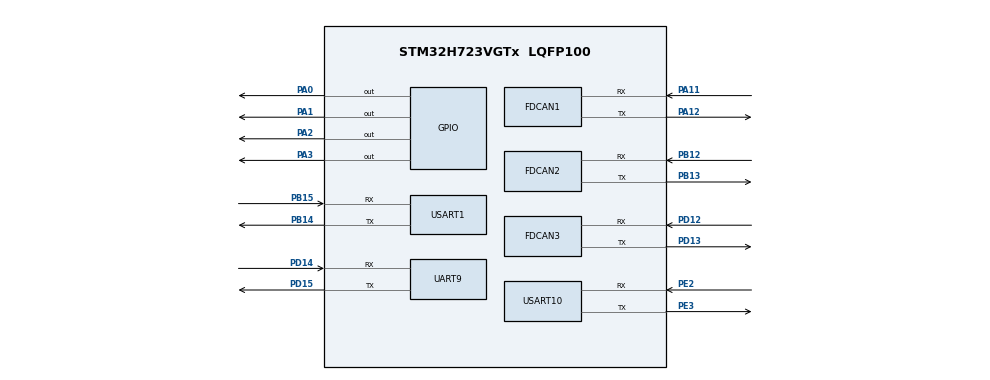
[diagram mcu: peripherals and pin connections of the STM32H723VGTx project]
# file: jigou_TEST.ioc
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CORTEX_M7.default_mode_Activation=1
FDCAN1.CalculateBaudRateNominal=1000000
FDCAN1.CalculateTimeBitNominal=1000
FDCAN1.CalculateTimeQuantumNominal=50.0
FDCAN1.ExtFiltersNbr=1
FDCAN1.NominalPrescaler=5
FDCAN1.NominalTimeSeg1=14
FDCAN1.NominalTimeSeg2=5
FDCAN1.RxBuffersNbr=0
FDCAN1.RxFifo0ElmtsNbr=32
FDCAN1.RxFifo1ElmtsNbr=0
FDCAN1.StdFiltersNbr=1
FDCAN1.TxFifoQueueElmtsNbr=8
FDCAN2.CalculateBaudRateNominal=2083333
FDCAN2.CalculateTimeBitNominal=480
FDCAN2.CalculateTimeQuantumNominal=160.0
FDCAN2.MessageRAMOffset=852
FDCAN3.CalculateBaudRateNominal=2083333
FDCAN3.CalculateTimeBitNominal=480
FDCAN3.CalculateTimeQuantumNominal=160.0
FDCAN3.MessageRAMOffset=1704
Mcu.Family=STM32H7
Mcu.Name=STM32H723VGTx
Mcu.Package=LQFP100
NVIC.FDCAN1_IT0_IRQn=true\:0\:0\:false\:false\:true\:true\:true\:true
NVIC.FDCAN2_IT0_IRQn=true\:0\:0\:false\:false\:true\:true\:true\:true
NVIC.FDCAN3_IT0_IRQn=true\:0\:0\:false\:false\:true\:true\:true\:true
NVIC.PriorityGroup=NVIC_PRIORITYGROUP_4
NVIC.USART10_IRQn=true\:0\:0\:false\:false\:true\:true\:true\:true
NVIC.USART1_IRQn=true\:0\:0\:false\:false\:true\:true\:true\:true
PA0.GPIO_PuPd=GPIO_PULLDOWN
PA0.Signal=GPIO_Output
PA1.GPIO_PuPd=GPIO_PULLDOWN
PA1.Signal=GPIO_Output
PA11.Mode=FDCAN_Activate
PA11.Signal=FDCAN1_RX
PA12.Mode=FDCAN_Activate
PA12.Signal=FDCAN1_TX
PA13(JTMS/SWDIO).Mode=Serial_Wire
PA13(JTMS/SWDIO).Signal=DEBUG_JTMS-SWDIO
PA14(JTCK/SWCLK).Mode=Serial_Wire
PA14(JTCK/SWCLK).Signal=DEBUG_JTCK-SWCLK
PA2.GPIO_PuPd=GPIO_PULLDOWN
PA2.Signal=GPIO_Output
PA3.GPIO_PuPd=GPIO_PULLDOWN
PA3.Signal=GPIO_Output
PB12.Mode=FDCAN_Activate
PB12.Signal=FDCAN2_RX
PB13.Mode=FDCAN_Activate
PB13.Signal=FDCAN2_TX
PB14.Mode=Asynchronous
PB14.Signal=USART1_TX
PB15.Mode=Asynchronous
PB15.Signal=USART1_RX
PD12.Mode=FDCAN_Activate
PD12.Signal=FDCAN3_RX
PD13.Mode=FDCAN_Activate
PD13.Signal=FDCAN3_TX
PD14.Mode=Asynchronous
PD14.Signal=UART9_RX
PD15.Mode=Asynchronous
PD15.Signal=UART9_TX
PE2.Mode=Asynchronous
PE2.Signal=USART10_RX
PE3.Mode=Asynchronous
PE3.Signal=USART10_TX
PH0-OSC_IN.Mode=HSE-External-Oscillator
PH0-OSC_IN.Signal=RCC_OSC_IN
PH1-OSC_OUT.Mode=HSE-External-Oscillator
PH1-OSC_OUT.Signal=RCC_OSC_OUT
ProjectManager.HeapSize=0x200
ProjectManager.StackSize=0x400
ProjectManager.TargetToolchain=MDK-ARM V5.32
RCC.ADCFreq_Value=250000000
RCC.APB1Freq_Value=125000000
RCC.APB2Freq_Value=125000000
RCC.APB3Freq_Value=125000000
RCC.APB4Freq_Value=125000000
RCC.CortexFreq_Value=500000000
RCC.D1PPRE=RCC_APB3_DIV2
RCC.D2PPRE1=RCC_APB1_DIV2
RCC.D2PPRE2=RCC_APB2_DIV2
RCC.D3PPRE=RCC_APB4_DIV2
RCC.DIVM1=5
RCC.DIVM2=5
RCC.DIVM3=8
RCC.DIVN1=100
RCC.DIVN2=100
RCC.DIVP1=1
RCC.DIVQ1=5
RCC.DIVQ2=5
RCC.DIVR1=5
RCC.HCLKFreq_Value=250000000
RCC.HPRE=RCC_HCLK_DIV2
RCC.PLL2FRACN=0
RCC.PLL3FRACN=0
RCC.PLLFRACN=0
RCC.PLLSourceVirtual=RCC_PLLSOURCE_HSE
RCC.SYSCLKFreq_VALUE=500000000
RCC.SYSCLKSource=RCC_SYSCLKSOURCE_PLLCLK
RCC.USBFreq_Value=100000000
USART1.VirtualMode-Asynchronous=VM_ASYNC
USART10.VirtualMode=VM_ASYNC
VP_MEMORYMAP_VS_MEMORYMAP.Mode=CurAppReg
VP_TIM6_VS_ClockSourceINT.Mode=Enable_Timer
board=custom

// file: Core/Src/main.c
/* USER CODE BEGIN Header */
/**
  ******************************************************************************
  * @file           : main.c
  * @brief          : Main program body
  ******************************************************************************
  * @attention
  *
  * Copyright (c) 2026 STMicroelectronics.
  * All rights reserved.
  *
  * This software is licensed under terms that can be found in the LICENSE file
  * in the root directory of this software component.
  * If no LICENSE file comes with this software, it is provided AS-IS.
  *
  ******************************************************************************
  */
/* USER CODE END Header */
#include "main.h"
#include "fdcan.h"
#include "tim.h"
#include "usart.h"
#include "gpio.h"

/* USER CODE BEGIN Includes */
#include "my_main.h"
#include "vofa.h"
/* USER CODE END Includes */

/* USER CODE BEGIN PV */

static uint8_t vofa_rx_byte;

/* USER CODE END PV */

void SystemClock_Config(void);
static void MPU_Config(void);

int main(void)
{

  /* MPU Configuration--------------------------------------------------------*/
  MPU_Config();

  /* MCU Configuration--------------------------------------------------------*/

  /* Reset of all peripherals, Initializes the Flash interface and the Systick. */
  HAL_Init();

  /* Configure the system clock */
  SystemClock_Config();

  /* Initialize all configured peripherals */
  MX_GPIO_Init();
  MX_FDCAN1_Init();
  MX_FDCAN2_Init();
  MX_FDCAN3_Init();
  MX_TIM6_Init();
  MX_USART1_UART_Init();
  MX_UART9_Init();
  MX_USART10_UART_Init();
  /* USER CODE BEGIN 2 */
  VOFA_Init();
  HAL_UART_Receive_IT(&huart10, &vofa_rx_byte, 1U);
  My_Init();
  /* USER CODE END 2 */

  /* Infinite loop */
  /* USER CODE BEGIN WHILE */
  while (1)
  {
    My_Loop();
    /* USER CODE END WHILE */

  }
}

void SystemClock_Config(void)
{
  RCC_OscInitTypeDef RCC_OscInitStruct = {0};
  RCC_ClkInitTypeDef RCC_ClkInitStruct = {0};

  /** Supply configuration update enable
  */
  HAL_PWREx_ConfigSupply(PWR_LDO_SUPPLY);

  /** Configure the main internal regulator output voltage
  */
  __HAL_PWR_VOLTAGESCALING_CONFIG(PWR_REGULATOR_VOLTAGE_SCALE0);

  while(!__HAL_PWR_GET_FLAG(PWR_FLAG_VOSRDY)) {}

  /** Initializes the RCC Oscillators according to the specified parameters
  * in the RCC_OscInitTypeDef structure.
  */
  RCC_OscInitStruct.OscillatorType = RCC_OSCILLATORTYPE_HSE;
  RCC_OscInitStruct.HSEState = RCC_HSE_ON;
  RCC_OscInitStruct.PLL.PLLState = RCC_PLL_ON;
  RCC_OscInitStruct.PLL.PLLSource = RCC_PLLSOURCE_HSE;
  RCC_OscInitStruct.PLL.PLLM = 5;
  RCC_OscInitStruct.PLL.PLLN = 100;
  RCC_OscInitStruct.PLL.PLLP = 1;
  RCC_OscInitStruct.PLL.PLLQ = 5;
  RCC_OscInitStruct.PLL.PLLR = 5;
  RCC_OscInitStruct.PLL.PLLRGE = RCC_PLL1VCIRANGE_2;
  RCC_OscInitStruct.PLL.PLLVCOSEL = RCC_PLL1VCOWIDE;
  RCC_OscInitStruct.PLL.PLLFRACN = 0;
  if (HAL_RCC_OscConfig(&RCC_OscInitStruct) != HAL_OK)
  {
    Error_Handler();
  }

  /** Initializes the CPU, AHB and APB buses clocks
  */
  RCC_ClkInitStruct.ClockType = RCC_CLOCKTYPE_HCLK|RCC_CLOCKTYPE_SYSCLK
                              |RCC_CLOCKTYPE_PCLK1|RCC_CLOCKTYPE_PCLK2
                              |RCC_CLOCKTYPE_D3PCLK1|RCC_CLOCKTYPE_D1PCLK1;
  RCC_ClkInitStruct.SYSCLKSource = RCC_SYSCLKSOURCE_PLLCLK;
  RCC_ClkInitStruct.SYSCLKDivider = RCC_SYSCLK_DIV1;
  RCC_ClkInitStruct.AHBCLKDivider = RCC_HCLK_DIV2;
  RCC_ClkInitStruct.APB3CLKDivider = RCC_APB3_DIV2;
  RCC_ClkInitStruct.APB1CLKDivider = RCC_APB1_DIV2;
  RCC_ClkInitStruct.APB2CLKDivider = RCC_APB2_DIV2;
  RCC_ClkInitStruct.APB4CLKDivider = RCC_APB4_DIV2;

  if (HAL_RCC_ClockConfig(&RCC_ClkInitStruct, FLASH_LATENCY_3) != HAL_OK)
  {
    Error_Handler();
  }
}

/* USER CODE BEGIN 4 */

void HAL_UART_RxCpltCallback(UART_HandleTypeDef *huart)
{
  if (huart == &huart10)
  {
    VOFA_ParseByte(vofa_rx_byte);
    HAL_UART_Receive_IT(&huart10, &vofa_rx_byte, 1U);
  }
}

/* USER CODE END 4 */

 /* MPU Configuration */

void MPU_Config(void)
{
  MPU_Region_InitTypeDef MPU_InitStruct = {0};

  /* Disables the MPU */
  HAL_MPU_Disable();

  /** Initializes and configures the Region and the memory to be protected
  */
  MPU_InitStruct.Enable = MPU_REGION_ENABLE;
  MPU_InitStruct.Number = MPU_REGION_NUMBER0;
  MPU_InitStruct.BaseAddress = 0x0;
  MPU_InitStruct.Size = MPU_REGION_SIZE_4GB;
  MPU_InitStruct.SubRegionDisable = 0x87;
  MPU_InitStruct.TypeExtField = MPU_TEX_LEVEL0;
  MPU_InitStruct.AccessPermission = MPU_REGION_NO_ACCESS;
  MPU_InitStruct.DisableExec = MPU_INSTRUCTION_ACCESS_DISABLE;
  MPU_InitStruct.IsShareable = MPU_ACCESS_SHAREABLE;
  MPU_InitStruct.IsCacheable = MPU_ACCESS_NOT_CACHEABLE;
  MPU_InitStruct.IsBufferable = MPU_ACCESS_NOT_BUFFERABLE;

  HAL_MPU_ConfigRegion(&MPU_InitStruct);
  /* Enables the MPU */
  HAL_MPU_Enable(MPU_PRIVILEGED_DEFAULT);

}

void Error_Handler(void)
{
  __disable_irq();
  while (1)
  {
  }
}
